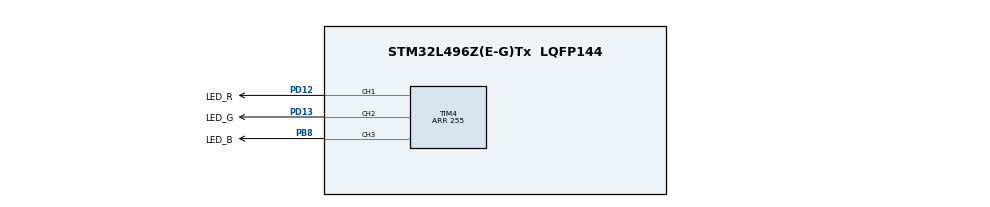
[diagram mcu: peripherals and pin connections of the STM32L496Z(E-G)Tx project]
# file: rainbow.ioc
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Mcu.Family=STM32L4
Mcu.Name=STM32L496Z(E-G)Tx
Mcu.Package=LQFP144
NVIC.PriorityGroup=NVIC_PRIORITYGROUP_4
PB8.GPIO_Label=LED_B
PB8.Signal=S_TIM4_CH3
PD12.GPIO_Label=LED_R
PD12.Signal=S_TIM4_CH1
PD13.GPIO_Label=LED_G
PD13.Signal=S_TIM4_CH2
ProjectManager.HeapSize=0x200
ProjectManager.StackSize=0x400
ProjectManager.TargetToolchain=STM32CubeIDE
RCC.HSE_VALUE=8000000
RCC.HSI48_VALUE=48000000
RCC.HSI_VALUE=16000000
RCC.LSE_VALUE=32768
RCC.MSI_VALUE=4000000
RCC.VCOOutputFreq_Value=32000000
SH.S_TIM4_CH1.0=TIM4_CH1,PWM Generation1 CH1
SH.S_TIM4_CH2.0=TIM4_CH2,PWM Generation2 CH2
SH.S_TIM4_CH3.0=TIM4_CH3,PWM Generation3 CH3
TIM4.Channel-PWM\ Generation1\ CH1=TIM_CHANNEL_1
TIM4.Channel-PWM\ Generation2\ CH2=TIM_CHANNEL_2
TIM4.Channel-PWM\ Generation3\ CH3=TIM_CHANNEL_3
TIM4.Period=255
TIM4.Pulse-PWM\ Generation2\ CH2=0
TIM4.Pulse-PWM\ Generation3\ CH3=0
VP_TIM4_VS_ClockSourceINT.Mode=Internal
board=custom

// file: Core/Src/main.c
/* USER CODE BEGIN Header */
/**
  ******************************************************************************
  * @file           : main.c
  * @brief          : Main program body
  ******************************************************************************
  * @attention
  *
  * <h2><center>&copy; Copyright (c) 2021 STMicroelectronics.
  * All rights reserved.</center></h2>
  *
  * This software component is licensed by ST under BSD 3-Clause license,
  * the "License"; You may not use this file except in compliance with the
  * License. You may obtain a copy of the License at:
  *                        opensource.org/licenses/BSD-3-Clause
  *
  ******************************************************************************
  */
/* USER CODE END Header */
#include "main.h"

TIM_HandleTypeDef htim4;

void SystemClock_Config(void);
static void MX_GPIO_Init(void);
static void MX_TIM4_Init(void);

/* USER CODE BEGIN 0 */

typedef struct {
    uint8_t red;
    uint8_t green;
    uint8_t blue;
}color_t;

static const color_t rainbow[] = {
        {.red=255, .green=0, .blue=0},
        {.red=255, .green=127, .blue=0},
        {.red=255, .green=255, .blue=0},
        {.red=127, .green=255, .blue=0},
        {.red=0, .green=255, .blue=0},
        {.red=0, .green=255, .blue=127},
        {.red=0, .green=255, .blue=255},
        {.red=0, .green=127, .blue=255},
        {.red=0, .green=0, .blue=255},
        {.red=127, .green=0, .blue=255},
        {.red=255, .green=0, .blue=255},
        {.red=255, .green=0, .blue=127}
};

static void set_color(const color_t * colors) {
    htim4.Instance->CCR1 = colors->red;
    htim4.Instance->CCR2 = colors->green;
    htim4.Instance->CCR3 = colors->blue;
}

/* USER CODE END 0 */

int main(void)
{

  /* MCU Configuration--------------------------------------------------------*/

  /* Reset of all peripherals, Initializes the Flash interface and the Systick. */
  HAL_Init();

  /* Configure the system clock */
  SystemClock_Config();

  /* Initialize all configured peripherals */
  MX_GPIO_Init();
  MX_TIM4_Init();
  /* USER CODE BEGIN 2 */
  if (HAL_OK != HAL_TIM_OC_Start(&htim4, TIM_CHANNEL_1)) {
      /* Starting Error */
      Error_Handler();
  }
  if (HAL_OK != HAL_TIM_OC_Start(&htim4, TIM_CHANNEL_2)) {
      /* Starting Error */
      Error_Handler();
  }
  if (HAL_OK != HAL_TIM_OC_Start(&htim4, TIM_CHANNEL_3)) {
      /* Starting Error */
      Error_Handler();
  }
  /* USER CODE END 2 */

  /* Infinite loop */
  /* USER CODE BEGIN WHILE */
  while (1)
  {
      for(uint8_t i=0; i<(sizeof(rainbow)/sizeof(rainbow[0])); i++) {
              set_color(&rainbow[i]);
              HAL_Delay(500);
      }
    /* USER CODE END WHILE */

  }
}

void SystemClock_Config(void)
{
  RCC_OscInitTypeDef RCC_OscInitStruct = {0};
  RCC_ClkInitTypeDef RCC_ClkInitStruct = {0};

  /** Initializes the RCC Oscillators according to the specified parameters
  * in the RCC_OscInitTypeDef structure.
  */
  RCC_OscInitStruct.OscillatorType = RCC_OSCILLATORTYPE_MSI;
  RCC_OscInitStruct.MSIState = RCC_MSI_ON;
  RCC_OscInitStruct.MSICalibrationValue = 0;
  RCC_OscInitStruct.MSIClockRange = RCC_MSIRANGE_6;
  RCC_OscInitStruct.PLL.PLLState = RCC_PLL_NONE;
  if (HAL_RCC_OscConfig(&RCC_OscInitStruct) != HAL_OK)
  {
    Error_Handler();
  }
  /** Initializes the CPU, AHB and APB buses clocks
  */
  RCC_ClkInitStruct.ClockType = RCC_CLOCKTYPE_HCLK|RCC_CLOCKTYPE_SYSCLK
                              |RCC_CLOCKTYPE_PCLK1|RCC_CLOCKTYPE_PCLK2;
  RCC_ClkInitStruct.SYSCLKSource = RCC_SYSCLKSOURCE_MSI;
  RCC_ClkInitStruct.AHBCLKDivider = RCC_SYSCLK_DIV1;
  RCC_ClkInitStruct.APB1CLKDivider = RCC_HCLK_DIV1;
  RCC_ClkInitStruct.APB2CLKDivider = RCC_HCLK_DIV1;

  if (HAL_RCC_ClockConfig(&RCC_ClkInitStruct, FLASH_LATENCY_0) != HAL_OK)
  {
    Error_Handler();
  }
  /** Configure the main internal regulator output voltage
  */
  if (HAL_PWREx_ControlVoltageScaling(PWR_REGULATOR_VOLTAGE_SCALE1) != HAL_OK)
  {
    Error_Handler();
  }
}

static void MX_TIM4_Init(void)
{

  TIM_ClockConfigTypeDef sClockSourceConfig = {0};
  TIM_MasterConfigTypeDef sMasterConfig = {0};
  TIM_OC_InitTypeDef sConfigOC = {0};

  htim4.Instance = TIM4;
  htim4.Init.Prescaler = 0;
  htim4.Init.CounterMode = TIM_COUNTERMODE_UP;
  htim4.Init.Period = 255;
  htim4.Init.ClockDivision = TIM_CLOCKDIVISION_DIV1;
  htim4.Init.AutoReloadPreload = TIM_AUTORELOAD_PRELOAD_DISABLE;
  if (HAL_TIM_Base_Init(&htim4) != HAL_OK)
  {
    Error_Handler();
  }
  sClockSourceConfig.ClockSource = TIM_CLOCKSOURCE_INTERNAL;
  if (HAL_TIM_ConfigClockSource(&htim4, &sClockSourceConfig) != HAL_OK)
  {
    Error_Handler();
  }
  if (HAL_TIM_PWM_Init(&htim4) != HAL_OK)
  {
    Error_Handler();
  }
  sMasterConfig.MasterOutputTrigger = TIM_TRGO_RESET;
  sMasterConfig.MasterSlaveMode = TIM_MASTERSLAVEMODE_DISABLE;
  if (HAL_TIMEx_MasterConfigSynchronization(&htim4, &sMasterConfig) != HAL_OK)
  {
    Error_Handler();
  }
  sConfigOC.OCMode = TIM_OCMODE_PWM1;
  sConfigOC.Pulse = 0;
  sConfigOC.OCPolarity = TIM_OCPOLARITY_HIGH;
  sConfigOC.OCFastMode = TIM_OCFAST_DISABLE;
  if (HAL_TIM_PWM_ConfigChannel(&htim4, &sConfigOC, TIM_CHANNEL_1) != HAL_OK)
  {
    Error_Handler();
  }
  if (HAL_TIM_PWM_ConfigChannel(&htim4, &sConfigOC, TIM_CHANNEL_2) != HAL_OK)
  {
    Error_Handler();
  }
  if (HAL_TIM_PWM_ConfigChannel(&htim4, &sConfigOC, TIM_CHANNEL_3) != HAL_OK)
  {
    Error_Handler();
  }
  HAL_TIM_MspPostInit(&htim4);

}

static void MX_GPIO_Init(void)
{

  /* GPIO Ports Clock Enable */
  __HAL_RCC_GPIOD_CLK_ENABLE();
  __HAL_RCC_GPIOB_CLK_ENABLE();

}

void Error_Handler(void)
{
  __disable_irq();
  while (1)
  {
  }
}

/************************ (C) COPYRIGHT STMicroelectronics *****END OF FILE****/
